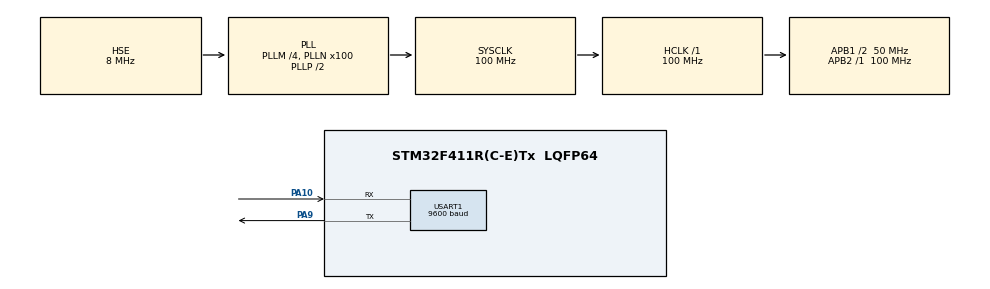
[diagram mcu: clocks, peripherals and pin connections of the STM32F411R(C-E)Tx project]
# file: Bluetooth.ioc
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Mcu.Family=STM32F4
Mcu.Name=STM32F411R(C-E)Tx
Mcu.Package=LQFP64
NVIC.PriorityGroup=NVIC_PRIORITYGROUP_4
PA10.Mode=Asynchronous
PA10.Signal=USART1_RX
PA13.Mode=Serial_Wire
PA13.Signal=SYS_JTMS-SWDIO
PA14.Mode=Serial_Wire
PA14.Signal=SYS_JTCK-SWCLK
PA9.Mode=Asynchronous
PA9.Signal=USART1_TX
PH0\ -\ OSC_IN.Mode=HSE-External-Oscillator
PH0\ -\ OSC_IN.Signal=RCC_OSC_IN
PH1\ -\ OSC_OUT.Mode=HSE-External-Oscillator
PH1\ -\ OSC_OUT.Signal=RCC_OSC_OUT
ProjectManager.HeapSize=0x200
ProjectManager.StackSize=0x400
ProjectManager.TargetToolchain=STM32CubeIDE
RCC.48MHZClocksFreq_Value=50000000
RCC.AHBFreq_Value=100000000
RCC.APB1CLKDivider=RCC_HCLK_DIV2
RCC.APB1Freq_Value=50000000
RCC.APB1TimFreq_Value=100000000
RCC.APB2Freq_Value=100000000
RCC.APB2TimFreq_Value=100000000
RCC.CortexFreq_Value=100000000
RCC.HCLKFreq_Value=100000000
RCC.HSE_VALUE=8000000
RCC.HSI_VALUE=16000000
RCC.LSE_VALUE=32768
RCC.PLLM=4
RCC.PLLN=100
RCC.PLLSourceVirtual=RCC_PLLSOURCE_HSE
RCC.SYSCLKFreq_VALUE=100000000
RCC.SYSCLKSource=RCC_SYSCLKSOURCE_PLLCLK
RCC.VCOOutputFreq_Value=200000000
USART1.BaudRate=9600
USART1.VirtualMode=VM_ASYNC
board=custom

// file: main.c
/* USER CODE BEGIN Header */
/**
  ******************************************************************************
  * @file           : main.c
  * @brief          : Main program body
  ******************************************************************************
  * @attention
  *
  * Copyright (c) 2025 STMicroelectronics.
  * All rights reserved.
  *
  * This software is licensed under terms that can be found in the LICENSE file
  * in the root directory of this software component.
  * If no LICENSE file comes with this software, it is provided AS-IS.
  *
  ******************************************************************************
  */
/* USER CODE END Header */
#include "main.h"
#include "usart.h"
#include "gpio.h"

/* USER CODE BEGIN Includes */
#include <string.h>

/* USER CODE END Includes */

/* USER CODE BEGIN PD */
#define RX_BUFFER_SIZE 64

/* USER CODE END PD */

/* USER CODE BEGIN PV */
uint8_t rxBuffer[RX_BUFFER_SIZE];  // UART 수신 버퍼
uint8_t receivedByte;              // 단일 바이트 저장 변수

/* USER CODE END PV */

void SystemClock_Config(void);

/* USER CODE BEGIN 0 */
void HAL_UART_RxCpltCallback(UART_HandleTypeDef *huart)
{
    if (huart->Instance == USART1)  // UART2 인터럽트 발생 시
    {
        HAL_UART_Transmit(&huart1, &receivedByte, 1, 10); // 수신된 문자 다시 출력 (에코)
        HAL_UART_Receive_IT(&huart1, &receivedByte, 1);   // 다음 문자 수신 대기
    }
}

void sendATCommand(UART_HandleTypeDef *huart, const char *command)
{
    HAL_UART_Transmit(huart, (uint8_t*)command, strlen(command), 100); // 명령어 전송
    HAL_UART_Transmit(huart, (uint8_t*)"\r\n", 2, 100); // CR/LF 추가
}

/* USER CODE END 0 */

int main(void)
{

  /* MCU Configuration--------------------------------------------------------*/

  /* Reset of all peripherals, Initializes the Flash interface and the Systick. */
  HAL_Init();

  /* Configure the system clock */
  SystemClock_Config();

  /* Initialize all configured peripherals */
  MX_GPIO_Init();
  MX_USART1_UART_Init();
  /* USER CODE BEGIN 2 */
  HAL_Delay(2000);  // 블루투스 모듈이 안정화될 시간을 확보
  HAL_UART_Receive_IT(&huart1, &receivedByte, 1);  // UART 인터럽트 기반 수신 활성화

  /* USER CODE END 2 */

  /* Infinite loop */
  /* USER CODE BEGIN WHILE */
  while (1)
  {
	  sendATCommand(&huart1, "AT");
	  HAL_Delay(2000);  // 2초마다 AT 명령어 전송

    /* USER CODE END WHILE */

  }
}

void SystemClock_Config(void)
{
  RCC_OscInitTypeDef RCC_OscInitStruct = {0};
  RCC_ClkInitTypeDef RCC_ClkInitStruct = {0};

  /** Configure the main internal regulator output voltage
  */
  __HAL_RCC_PWR_CLK_ENABLE();
  __HAL_PWR_VOLTAGESCALING_CONFIG(PWR_REGULATOR_VOLTAGE_SCALE1);

  /** Initializes the RCC Oscillators according to the specified parameters
  * in the RCC_OscInitTypeDef structure.
  */
  RCC_OscInitStruct.OscillatorType = RCC_OSCILLATORTYPE_HSE;
  RCC_OscInitStruct.HSEState = RCC_HSE_ON;
  RCC_OscInitStruct.PLL.PLLState = RCC_PLL_ON;
  RCC_OscInitStruct.PLL.PLLSource = RCC_PLLSOURCE_HSE;
  RCC_OscInitStruct.PLL.PLLM = 4;
  RCC_OscInitStruct.PLL.PLLN = 100;
  RCC_OscInitStruct.PLL.PLLP = RCC_PLLP_DIV2;
  RCC_OscInitStruct.PLL.PLLQ = 4;
  if (HAL_RCC_OscConfig(&RCC_OscInitStruct) != HAL_OK)
  {
    Error_Handler();
  }

  /** Initializes the CPU, AHB and APB buses clocks
  */
  RCC_ClkInitStruct.ClockType = RCC_CLOCKTYPE_HCLK|RCC_CLOCKTYPE_SYSCLK
                              |RCC_CLOCKTYPE_PCLK1|RCC_CLOCKTYPE_PCLK2;
  RCC_ClkInitStruct.SYSCLKSource = RCC_SYSCLKSOURCE_PLLCLK;
  RCC_ClkInitStruct.AHBCLKDivider = RCC_SYSCLK_DIV1;
  RCC_ClkInitStruct.APB1CLKDivider = RCC_HCLK_DIV2;
  RCC_ClkInitStruct.APB2CLKDivider = RCC_HCLK_DIV1;

  if (HAL_RCC_ClockConfig(&RCC_ClkInitStruct, FLASH_LATENCY_3) != HAL_OK)
  {
    Error_Handler();
  }
}

void Error_Handler(void)
{
  __disable_irq();
  while (1)
  {
  }
}
